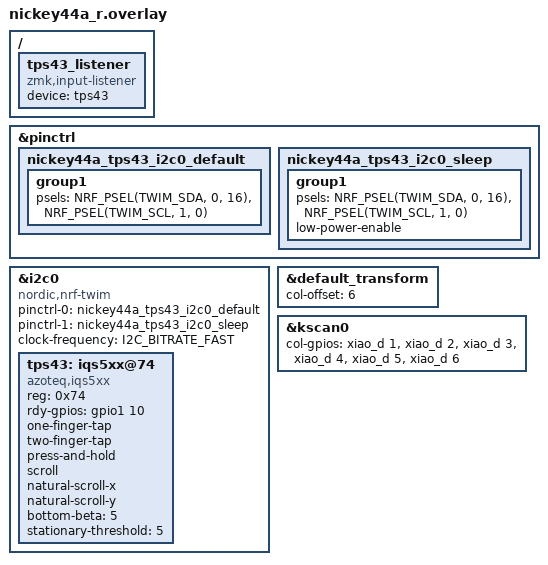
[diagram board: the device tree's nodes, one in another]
#include "nickey44a.dtsi"
#include <dt-bindings/pinctrl/nrf-pinctrl.h>

/*
 * TPS43 FPC breakout wiring:
 *   SCL = P1.00, SDA = P0.16, RDY = P1.10.
 * NRST is held high in hardware and is not controlled by the MCU.
 */

&pinctrl {
    nickey44a_tps43_i2c0_default: nickey44a_tps43_i2c0_default {
        group1 {
            psels = <NRF_PSEL(TWIM_SDA, 0, 16)>,
                    <NRF_PSEL(TWIM_SCL, 1, 0)>;
        };
    };

    nickey44a_tps43_i2c0_sleep: nickey44a_tps43_i2c0_sleep {
        group1 {
            psels = <NRF_PSEL(TWIM_SDA, 0, 16)>,
                    <NRF_PSEL(TWIM_SCL, 1, 0)>;
            low-power-enable;
        };
    };
};

/ {
    tps43_listener: tps43_listener {
        compatible = "zmk,input-listener";
        device = <&tps43>;
    };
};

&i2c0 {
    status = "okay";
    compatible = "nordic,nrf-twim";
    pinctrl-0 = <&nickey44a_tps43_i2c0_default>;
    pinctrl-1 = <&nickey44a_tps43_i2c0_sleep>;
    pinctrl-names = "default", "sleep";
    clock-frequency = <I2C_BITRATE_FAST>;
    #address-cells = <1>;
    #size-cells = <0>;

    tps43: iqs5xx@74 {
        compatible = "azoteq,iqs5xx";
        reg = <0x74>;
        rdy-gpios = <&gpio1 10 GPIO_ACTIVE_HIGH>;

        one-finger-tap;
        two-finger-tap;
        press-and-hold;
        scroll;
        natural-scroll-x;
        natural-scroll-y;

        bottom-beta = <5>;
        stationary-threshold = <5>;
    };
};

&default_transform {
    col-offset = <6>;
};

&kscan0 {
        col-gpios
            = <&xiao_d 1 GPIO_ACTIVE_HIGH>
            , <&xiao_d 2 GPIO_ACTIVE_HIGH>
            , <&xiao_d 3 GPIO_ACTIVE_HIGH>
            , <&xiao_d 4 GPIO_ACTIVE_HIGH>
            , <&xiao_d 5 GPIO_ACTIVE_HIGH>
            , <&xiao_d 6 GPIO_ACTIVE_HIGH>
            ;
};
